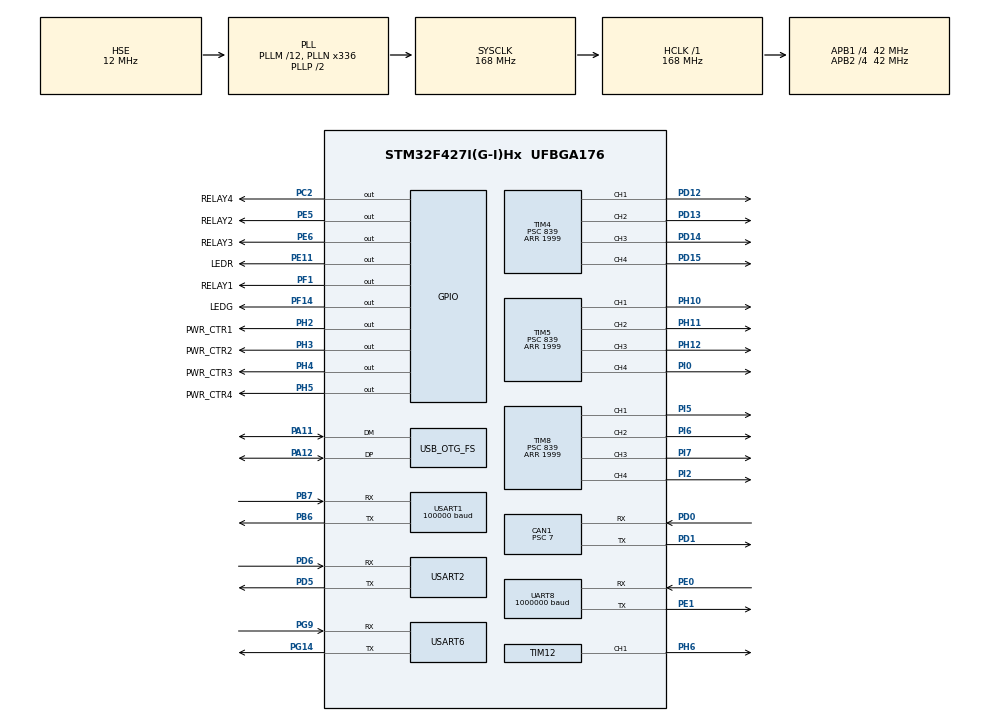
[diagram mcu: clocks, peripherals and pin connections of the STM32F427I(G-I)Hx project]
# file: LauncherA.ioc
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CAN1.BS1=CAN_BS1_3TQ
CAN1.BS2=CAN_BS2_2TQ
CAN1.CalculateBaudRate=999999
CAN1.CalculateTimeBit=1000
CAN1.CalculateTimeQuantum=166.66666666666669
CAN1.Prescaler=7
CAN1.SJW=CAN_SJW_1TQ
Dma.Request0=USART1_RX
Dma.Request1=UART8_TX
Dma.UART8_TX.1.Direction=DMA_MEMORY_TO_PERIPH
Dma.UART8_TX.1.FIFOMode=DMA_FIFOMODE_DISABLE
Dma.UART8_TX.1.Instance=DMA1_Stream0
Dma.UART8_TX.1.MemDataAlignment=DMA_MDATAALIGN_BYTE
Dma.UART8_TX.1.MemInc=DMA_MINC_ENABLE
Dma.UART8_TX.1.Mode=DMA_NORMAL
Dma.UART8_TX.1.PeriphDataAlignment=DMA_PDATAALIGN_BYTE
Dma.UART8_TX.1.PeriphInc=DMA_PINC_DISABLE
Dma.UART8_TX.1.Priority=DMA_PRIORITY_LOW
Dma.USART1_RX.0.Direction=DMA_PERIPH_TO_MEMORY
Dma.USART1_RX.0.FIFOMode=DMA_FIFOMODE_DISABLE
Dma.USART1_RX.0.Instance=DMA2_Stream2
Dma.USART1_RX.0.MemDataAlignment=DMA_MDATAALIGN_BYTE
Dma.USART1_RX.0.MemInc=DMA_MINC_ENABLE
Dma.USART1_RX.0.Mode=DMA_NORMAL
Dma.USART1_RX.0.PeriphDataAlignment=DMA_PDATAALIGN_BYTE
Dma.USART1_RX.0.PeriphInc=DMA_PINC_DISABLE
Dma.USART1_RX.0.Priority=DMA_PRIORITY_LOW
FREERTOS.HEAP_NUMBER=5
FREERTOS.INCLUDE_eTaskGetState=1
FREERTOS.INCLUDE_xTimerPendFunctionCall=1
FREERTOS.MEMORY_ALLOCATION=2
FREERTOS.Tasks01=defaultTask,0,2048,StartDefaultTask,As weak,NULL,Static,defaultTaskBuffer,defaultTaskControlBlock
FREERTOS.configENABLE_FPU=1
FREERTOS.configTOTAL_HEAP_SIZE=65536
FREERTOS.configUSE_TIMERS=1
Mcu.Family=STM32F4
Mcu.Name=STM32F427I(G-I)Hx
Mcu.Package=UFBGA176
NVIC.CAN1_RX0_IRQn=true\:10\:0\:true\:false\:true\:true\:true\:true\:true
NVIC.DMA1_Stream0_IRQn=true\:5\:0\:false\:false\:true\:true\:false\:true\:true
NVIC.DMA2_Stream2_IRQn=true\:5\:0\:false\:false\:true\:true\:false\:true\:true
NVIC.OTG_FS_IRQn=true\:9\:0\:true\:false\:true\:true\:false\:true\:true
NVIC.PriorityGroup=NVIC_PRIORITYGROUP_4
NVIC.TIM6_DAC_IRQn=true\:12\:0\:true\:false\:true\:true\:true\:true\:true
NVIC.TIM7_IRQn=true\:11\:0\:true\:false\:true\:true\:true\:true\:true
NVIC.UART8_IRQn=true\:14\:0\:true\:false\:true\:true\:true\:true\:true
NVIC.USART1_IRQn=true\:13\:0\:true\:false\:true\:true\:true\:true\:true
PA11.Mode=Device_Only
PA11.Signal=USB_OTG_FS_DM
PA12.Mode=Device_Only
PA12.Signal=USB_OTG_FS_DP
PA13.Mode=Serial_Wire
PA13.Signal=SYS_JTMS-SWDIO
PA14.Mode=Serial_Wire
PA14.Signal=SYS_JTCK-SWCLK
PB6.Mode=Asynchronous
PB6.Signal=USART1_TX
PB7.Mode=Asynchronous
PB7.Signal=USART1_RX
PC2.GPIO_Label=RELAY4
PC2.PinState=GPIO_PIN_RESET
PC2.Signal=GPIO_Output
PD0.Mode=CAN_Activate
PD0.Signal=CAN1_RX
PD1.Mode=CAN_Activate
PD1.Signal=CAN1_TX
PD12.Signal=S_TIM4_CH1
PD13.Signal=S_TIM4_CH2
PD14.Signal=S_TIM4_CH3
PD15.Signal=S_TIM4_CH4
PD5.Mode=Asynchronous
PD5.Signal=USART2_TX
PD6.Mode=Asynchronous
PD6.Signal=USART2_RX
PE0.Mode=Asynchronous
PE0.Signal=UART8_RX
PE1.Mode=Asynchronous
PE1.Signal=UART8_TX
PE11.GPIO_Label=LEDR
PE11.Signal=GPIO_Output
PE5.GPIO_Label=RELAY2
PE5.PinState=GPIO_PIN_RESET
PE5.Signal=GPIO_Output
PE6.GPIO_Label=RELAY3
PE6.PinState=GPIO_PIN_RESET
PE6.Signal=GPIO_Output
PF1.GPIO_Label=RELAY1
PF1.PinState=GPIO_PIN_RESET
PF1.Signal=GPIO_Output
PF14.GPIO_Label=LEDG
PF14.Signal=GPIO_Output
PG14.Mode=Asynchronous
PG14.Signal=USART6_TX
PG9.Mode=Asynchronous
PG9.Signal=USART6_RX
PH0/OSC_IN.Mode=HSE-External-Oscillator
PH0/OSC_IN.Signal=RCC_OSC_IN
PH1/OSC_OUT.Mode=HSE-External-Oscillator
PH1/OSC_OUT.Signal=RCC_OSC_OUT
PH10.Signal=S_TIM5_CH1
PH11.Signal=S_TIM5_CH2
PH12.Signal=S_TIM5_CH3
PH2.GPIO_Label=PWR_CTR1
PH2.Signal=GPIO_Output
PH3.GPIO_Label=PWR_CTR2
PH3.Signal=GPIO_Output
PH4.GPIO_Label=PWR_CTR3
PH4.Signal=GPIO_Output
PH5.GPIO_Label=PWR_CTR4
PH5.Signal=GPIO_Output
PH6.Signal=S_TIM12_CH1
PI0.Signal=S_TIM5_CH4
PI2.Signal=S_TIM8_CH4
PI5.Signal=S_TIM8_CH1
PI6.Signal=S_TIM8_CH2
PI7.Signal=S_TIM8_CH3
ProjectManager.HeapSize=0x200
ProjectManager.StackSize=0x400
ProjectManager.TargetToolchain=CMake
RCC.48MHZClocksFreq_Value=48000000
RCC.AHBFreq_Value=168000000
RCC.APB1CLKDivider=RCC_HCLK_DIV4
RCC.APB1Freq_Value=42000000
RCC.APB1TimFreq_Value=84000000
RCC.APB2CLKDivider=RCC_HCLK_DIV4
RCC.APB2Freq_Value=42000000
RCC.APB2TimFreq_Value=84000000
RCC.CortexFreq_Value=168000000
RCC.HCLKFreq_Value=168000000
RCC.HSE_VALUE=12000000
RCC.HSI_VALUE=16000000
RCC.LSE_VALUE=32768
RCC.PLLM=12
RCC.PLLN=336
RCC.PLLQ=7
RCC.SYSCLKFreq_VALUE=168000000
RCC.SYSCLKSource=RCC_SYSCLKSOURCE_PLLCLK
RCC.VCOOutputFreq_Value=336000000
SH.S_TIM12_CH1.0=TIM12_CH1,PWM Generation1 CH1
SH.S_TIM4_CH1.0=TIM4_CH1,PWM Generation1 CH1
SH.S_TIM4_CH2.0=TIM4_CH2,PWM Generation2 CH2
SH.S_TIM4_CH3.0=TIM4_CH3,PWM Generation3 CH3
SH.S_TIM4_CH4.0=TIM4_CH4,PWM Generation4 CH4
SH.S_TIM5_CH1.0=TIM5_CH1,PWM Generation1 CH1
SH.S_TIM5_CH2.0=TIM5_CH2,PWM Generation2 CH2
SH.S_TIM5_CH3.0=TIM5_CH3,PWM Generation3 CH3
SH.S_TIM5_CH4.0=TIM5_CH4,PWM Generation4 CH4
SH.S_TIM8_CH1.0=TIM8_CH1,PWM Generation1 CH1
SH.S_TIM8_CH2.0=TIM8_CH2,PWM Generation2 CH2
SH.S_TIM8_CH3.0=TIM8_CH3,PWM Generation3 CH3
SH.S_TIM8_CH4.0=TIM8_CH4,PWM Generation4 CH4
TIM12.Channel-PWM\ Generation1\ CH1=TIM_CHANNEL_1
TIM12.Prescaler=83
TIM2.Prescaler=83
TIM4.Channel-PWM\ Generation1\ CH1=TIM_CHANNEL_1
TIM4.Channel-PWM\ Generation2\ CH2=TIM_CHANNEL_2
TIM4.Channel-PWM\ Generation3\ CH3=TIM_CHANNEL_3
TIM4.Channel-PWM\ Generation4\ CH4=TIM_CHANNEL_4
TIM4.Period=1999
TIM4.Prescaler=839
TIM5.Channel-PWM\ Generation1\ CH1=TIM_CHANNEL_1
TIM5.Channel-PWM\ Generation2\ CH2=TIM_CHANNEL_2
TIM5.Channel-PWM\ Generation3\ CH3=TIM_CHANNEL_3
TIM5.Channel-PWM\ Generation4\ CH4=TIM_CHANNEL_4
TIM5.Period=1999
TIM5.Prescaler=839
TIM6.Period=4999
TIM6.Prescaler=83
TIM7.Period=999
TIM7.Prescaler=83
TIM8.Channel-PWM\ Generation1\ CH1=TIM_CHANNEL_1
TIM8.Channel-PWM\ Generation2\ CH2=TIM_CHANNEL_2
TIM8.Channel-PWM\ Generation3\ CH3=TIM_CHANNEL_3
TIM8.Channel-PWM\ Generation4\ CH4=TIM_CHANNEL_4
TIM8.Period=1999
TIM8.Prescaler=839
UART8.BaudRate=1000000
UART8.VirtualMode=Asynchronous
USART1.BaudRate=100000
USART1.Mode=MODE_RX
USART1.Parity=PARITY_EVEN
USART1.VirtualMode=VM_ASYNC
USART1.WordLength=WORDLENGTH_9B
USART2.VirtualMode=VM_ASYNC
USART6.VirtualMode=VM_ASYNC
USB_DEVICE.CLASS_NAME_FS=CDC
USB_DEVICE.VirtualMode-CDC_FS=Cdc
USB_DEVICE.VirtualModeFS=Cdc_FS
USB_OTG_FS.VirtualMode=Device_Only
VP_FREERTOS_VS_CMSIS_V1.Mode=CMSIS_V1
VP_TIM12_VS_ClockSourceINT.Mode=Internal
VP_TIM2_VS_ClockSourceINT.Mode=Internal
VP_TIM4_VS_ClockSourceINT.Mode=Internal
VP_TIM5_VS_ClockSourceINT.Mode=Internal
VP_TIM6_VS_ClockSourceINT.Mode=Enable_Timer
VP_TIM7_VS_ClockSourceINT.Mode=Enable_Timer
VP_TIM8_VS_ClockSourceINT.Mode=Internal
VP_USB_DEVICE_VS_USB_DEVICE_CDC_FS.Mode=CDC_FS
board=custom

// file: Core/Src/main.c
/* USER CODE BEGIN Header */
/**
  ******************************************************************************
  * @file           : main.c
  * @brief          : Main program body
  ******************************************************************************
  * @attention
  *
  * Copyright (c) 2026 STMicroelectronics.
  * All rights reserved.
  *
  * This software is licensed under terms that can be found in the LICENSE file
  * in the root directory of this software component.
  * If no LICENSE file comes with this software, it is provided AS-IS.
  *
  ******************************************************************************
  */
/* USER CODE END Header */
#include "main.h"
#include "cmsis_os.h"
#include "can.h"
#include "dma.h"
#include "tim.h"
#include "usart.h"
#include "usb_device.h"
#include "gpio.h"

void SystemClock_Config(void);
void MX_FREERTOS_Init(void);
/* USER CODE BEGIN PFP */
int _write(int file, char *ptr, int len) {
  HAL_UART_Transmit_DMA(&huart8, (uint8_t*)ptr, len);
  while (HAL_UART_GetState(&huart8) != HAL_UART_STATE_READY) {}
  return len;
}
/* USER CODE END PFP */

int main(void)
{

  /* MCU Configuration--------------------------------------------------------*/

  /* Reset of all peripherals, Initializes the Flash interface and the Systick. */
  HAL_Init();

  /* Configure the system clock */
  SystemClock_Config();

  /* Initialize all configured peripherals */
  MX_GPIO_Init();
  MX_DMA_Init();
  MX_USART1_UART_Init();
  MX_TIM4_Init();
  MX_TIM5_Init();
  MX_UART8_Init();
  MX_CAN1_Init();
  MX_USART6_UART_Init();
  MX_TIM2_Init();
  MX_USART2_UART_Init();
  MX_TIM12_Init();
  MX_TIM7_Init();
  MX_TIM8_Init();
  MX_TIM6_Init();

  /* Call init function for freertos objects (in cmsis_os2.c) */
  MX_FREERTOS_Init();

  /* Start scheduler */
  osKernelStart();

  /* We should never get here as control is now taken by the scheduler */

  /* Infinite loop */
  while (1)
  {

  }
}

void SystemClock_Config(void)
{
  RCC_OscInitTypeDef RCC_OscInitStruct = {0};
  RCC_ClkInitTypeDef RCC_ClkInitStruct = {0};

  /** Configure the main internal regulator output voltage
  */
  __HAL_RCC_PWR_CLK_ENABLE();
  __HAL_PWR_VOLTAGESCALING_CONFIG(PWR_REGULATOR_VOLTAGE_SCALE1);

  /** Initializes the RCC Oscillators according to the specified parameters
  * in the RCC_OscInitTypeDef structure.
  */
  RCC_OscInitStruct.OscillatorType = RCC_OSCILLATORTYPE_HSE;
  RCC_OscInitStruct.HSEState = RCC_HSE_ON;
  RCC_OscInitStruct.PLL.PLLState = RCC_PLL_ON;
  RCC_OscInitStruct.PLL.PLLSource = RCC_PLLSOURCE_HSE;
  RCC_OscInitStruct.PLL.PLLM = 12;
  RCC_OscInitStruct.PLL.PLLN = 336;
  RCC_OscInitStruct.PLL.PLLP = RCC_PLLP_DIV2;
  RCC_OscInitStruct.PLL.PLLQ = 7;
  if (HAL_RCC_OscConfig(&RCC_OscInitStruct) != HAL_OK)
  {
    Error_Handler();
  }

  /** Initializes the CPU, AHB and APB buses clocks
  */
  RCC_ClkInitStruct.ClockType = RCC_CLOCKTYPE_HCLK|RCC_CLOCKTYPE_SYSCLK
                              |RCC_CLOCKTYPE_PCLK1|RCC_CLOCKTYPE_PCLK2;
  RCC_ClkInitStruct.SYSCLKSource = RCC_SYSCLKSOURCE_PLLCLK;
  RCC_ClkInitStruct.AHBCLKDivider = RCC_SYSCLK_DIV1;
  RCC_ClkInitStruct.APB1CLKDivider = RCC_HCLK_DIV4;
  RCC_ClkInitStruct.APB2CLKDivider = RCC_HCLK_DIV4;

  if (HAL_RCC_ClockConfig(&RCC_ClkInitStruct, FLASH_LATENCY_5) != HAL_OK)
  {
    Error_Handler();
  }
}

void Error_Handler(void)
{
  __disable_irq();
  while (1)
  {
  }
}

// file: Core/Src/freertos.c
/* USER CODE BEGIN Header */
/**
  ******************************************************************************
  * File Name          : freertos.c
  * Description        : Code for freertos applications
  ******************************************************************************
  * @attention
  *
  * Copyright (c) 2026 STMicroelectronics.
  * All rights reserved.
  *
  * This software is licensed under terms that can be found in the LICENSE file
  * in the root directory of this software component.
  * If no LICENSE file comes with this software, it is provided AS-IS.
  *
  ******************************************************************************
  */
/* USER CODE END Header */

#include "FreeRTOS.h"
#include "task.h"
#include "main.h"
#include "cmsis_os.h"

osThreadId defaultTaskHandle;
uint32_t defaultTaskBuffer[ 2048 ];
osStaticThreadDef_t defaultTaskControlBlock;

void StartDefaultTask(void const * argument);

extern void MX_USB_DEVICE_Init(void);
void MX_FREERTOS_Init(void); /* (MISRA C 2004 rule 8.1) */

/* GetIdleTaskMemory prototype (linked to static allocation support) */
void vApplicationGetIdleTaskMemory( StaticTask_t **ppxIdleTaskTCBBuffer, StackType_t **ppxIdleTaskStackBuffer, uint32_t *pulIdleTaskStackSize );

/* GetTimerTaskMemory prototype (linked to static allocation support) */
void vApplicationGetTimerTaskMemory( StaticTask_t **ppxTimerTaskTCBBuffer, StackType_t **ppxTimerTaskStackBuffer, uint32_t *pulTimerTaskStackSize );

/* USER CODE BEGIN GET_IDLE_TASK_MEMORY */
static StaticTask_t xIdleTaskTCBBuffer;
static StackType_t xIdleStack[configMINIMAL_STACK_SIZE];

void vApplicationGetIdleTaskMemory( StaticTask_t **ppxIdleTaskTCBBuffer, StackType_t **ppxIdleTaskStackBuffer, uint32_t *pulIdleTaskStackSize )
{
  *ppxIdleTaskTCBBuffer = &xIdleTaskTCBBuffer;
  *ppxIdleTaskStackBuffer = &xIdleStack[0];
  *pulIdleTaskStackSize = configMINIMAL_STACK_SIZE;
  /* place for user code */
}
/* USER CODE END GET_IDLE_TASK_MEMORY */

/* USER CODE BEGIN GET_TIMER_TASK_MEMORY */
static StaticTask_t xTimerTaskTCBBuffer;
static StackType_t xTimerStack[configTIMER_TASK_STACK_DEPTH];

void vApplicationGetTimerTaskMemory( StaticTask_t **ppxTimerTaskTCBBuffer, StackType_t **ppxTimerTaskStackBuffer, uint32_t *pulTimerTaskStackSize )
{
  *ppxTimerTaskTCBBuffer = &xTimerTaskTCBBuffer;
  *ppxTimerTaskStackBuffer = &xTimerStack[0];
  *pulTimerTaskStackSize = configTIMER_TASK_STACK_DEPTH;
  /* place for user code */
}
/* USER CODE END GET_TIMER_TASK_MEMORY */

void MX_FREERTOS_Init(void) {

  /* Create the thread(s) */
  /* definition and creation of defaultTask */
  osThreadStaticDef(defaultTask, StartDefaultTask, osPriorityNormal, 0, 2048, defaultTaskBuffer, &defaultTaskControlBlock);
  defaultTaskHandle = osThreadCreate(osThread(defaultTask), NULL);

}

__weak void StartDefaultTask(void const * argument)
{
  /* init code for USB_DEVICE */
  MX_USB_DEVICE_Init();
  for(;;)
  {
    osDelay(1);
  }
}
